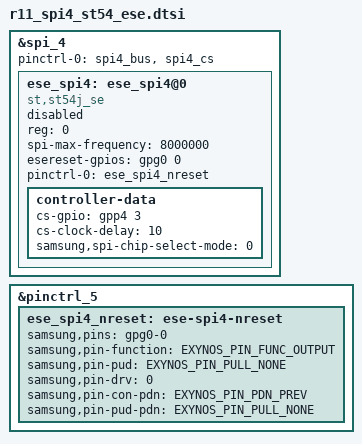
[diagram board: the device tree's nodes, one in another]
/*
 * Device Tree config for the ST54J/ST33 NFC eSE chip
 */

#include <dt-bindings/pinctrl/samsung.h>

/*******/
/* eSE */
/*******/

&spi_4 {
	#address-cells = <1>;
	#size-cells = <0>;
	status = "ok";
	pinctrl-names = "default";
	pinctrl-0 = <&spi4_bus &spi4_cs>;

	ese_spi4: ese_spi4@0 {
		compatible = "st,st54j_se";
		reg = <0>;
		spi-max-frequency = <8000000>;		/* Arbitrary SPI CLK FREQ */
		esereset-gpios = <&gpg0 0 0x00>;	/* SOC_NFC_ESE_RST_L */
		pinctrl-names = "default";
		pinctrl-0 = <&ese_spi4_nreset>;
		status = "disabled";

		controller-data {
			cs-gpio = <&gpp4 3 0>;
			cs-clock-delay = <10>;
			samsung,spi-chip-select-mode = <0>;
		};
	};
};

&pinctrl_5 {
	/* SOC_NFC_ESE_RST_L */
	ese_spi4_nreset: ese-spi4-nreset {
		samsung,pins = "gpg0-0";
		samsung,pin-function = <EXYNOS_PIN_FUNC_OUTPUT>;
		samsung,pin-pud = <EXYNOS_PIN_PULL_NONE>;
		samsung,pin-drv = <0>;	/* LVL1 DRV */
		samsung,pin-con-pdn = <EXYNOS_PIN_PDN_PREV>;
		samsung,pin-pud-pdn = <EXYNOS_PIN_PULL_NONE>;
	};
};
